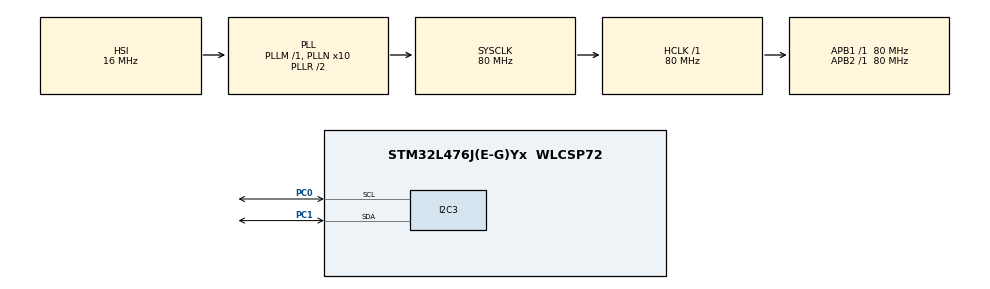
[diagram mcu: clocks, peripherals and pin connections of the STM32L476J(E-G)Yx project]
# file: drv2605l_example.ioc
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I2C3.Timing=0x10909CEC
Mcu.Family=STM32L4
Mcu.Name=STM32L476J(E-G)Yx
Mcu.Package=WLCSP72
NVIC.PriorityGroup=NVIC_PRIORITYGROUP_4
PC0.Mode=I2C
PC0.Signal=I2C3_SCL
PC1.Mode=I2C
PC1.Signal=I2C3_SDA
ProjectManager.HeapSize=0x200
ProjectManager.StackSize=0x400
ProjectManager.TargetToolchain=STM32CubeIDE
RCC.ADCFreq_Value=64000000
RCC.AHBFreq_Value=80000000
RCC.APB1Freq_Value=80000000
RCC.APB1TimFreq_Value=80000000
RCC.APB2Freq_Value=80000000
RCC.APB2TimFreq_Value=80000000
RCC.CortexFreq_Value=80000000
RCC.HCLKFreq_Value=80000000
RCC.HSE_VALUE=8000000
RCC.HSI_VALUE=16000000
RCC.LSE_VALUE=32768
RCC.MSI_VALUE=4000000
RCC.PLLN=10
RCC.PLLSourceVirtual=RCC_PLLSOURCE_HSI
RCC.SYSCLKFreq_VALUE=80000000
RCC.SYSCLKSource=RCC_SYSCLKSOURCE_PLLCLK
RCC.USBFreq_Value=64000000
RCC.VCOOutputFreq_Value=160000000
board=custom

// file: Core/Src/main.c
/* USER CODE BEGIN Header */
/**
  ******************************************************************************
  * @file           : main.c
  * @brief          : Main program body
  ******************************************************************************
  * @attention
  *
  * <h2><center>&copy; Copyright (c) 2021 STMicroelectronics.
  * All rights reserved.</center></h2>
  *
  * This software component is licensed by ST under BSD 3-Clause license,
  * the "License"; You may not use this file except in compliance with the
  * License. You may obtain a copy of the License at:
  *                        opensource.org/licenses/BSD-3-Clause
  *
  ******************************************************************************
  */
/* USER CODE END Header */
#include "main.h"

/* USER CODE BEGIN Includes */
#include "drv2605l.h"
/* USER CODE END Includes */

I2C_HandleTypeDef hi2c3;

void SystemClock_Config(void);
static void MX_GPIO_Init(void);
static void MX_I2C3_Init(void);

int main(void)
{

  /* MCU Configuration--------------------------------------------------------*/

  /* Reset of all peripherals, Initializes the Flash interface and the Systick. */
  HAL_Init();

  /* Configure the system clock */
  SystemClock_Config();

  /* Initialize all configured peripherals */
  MX_GPIO_Init();
  MX_I2C3_Init();
  HAL_I2C_Init(&hi2c3);
  /* USER CODE BEGIN 2 */

  drv2605l_init(&hi2c3); // Initialize the drv2605l with the correct I2C config

	drv2605l_set_mode(0x0); // Set mode to internal trigger input

	drv2605l_motor_select(0x36); // ERM Motor

	drv2605l_set_library(0x02); // Select ERM library. 1-5 & 7 for ERM motors, 6 for LRA motors

	int seq, wave;
  /* USER CODE END 2 */

  /* Infinite loop */
  while (1)
  {
  	seq = 0; // There are 8 sequence registers that can queue up to 8 waveforms
		for (wave = 1; wave <= 123; wave++) // There are 123 waveform effects
		{
			drv2605l_set_waveform(seq, wave);
			drv2605l_go();
			HAL_Delay(800); // Give it enough time to play waveform effect

			if (wave%8 == 0) // Each waveform register can queue 8 effects
			{
				seq++;
			}
			if (wave%64 == 0) // After the last register is used start over
			{
				seq = 0;
			}
		}
  }
}

void SystemClock_Config(void)
{
  RCC_OscInitTypeDef RCC_OscInitStruct = {0};
  RCC_ClkInitTypeDef RCC_ClkInitStruct = {0};

  /** Configure the main internal regulator output voltage
  */
  if (HAL_PWREx_ControlVoltageScaling(PWR_REGULATOR_VOLTAGE_SCALE1) != HAL_OK)
  {
    Error_Handler();
  }
  /** Initializes the RCC Oscillators according to the specified parameters
  * in the RCC_OscInitTypeDef structure.
  */
  RCC_OscInitStruct.OscillatorType = RCC_OSCILLATORTYPE_HSI;
  RCC_OscInitStruct.HSIState = RCC_HSI_ON;
  RCC_OscInitStruct.HSICalibrationValue = RCC_HSICALIBRATION_DEFAULT;
  RCC_OscInitStruct.PLL.PLLState = RCC_PLL_ON;
  RCC_OscInitStruct.PLL.PLLSource = RCC_PLLSOURCE_HSI;
  RCC_OscInitStruct.PLL.PLLM = 1;
  RCC_OscInitStruct.PLL.PLLN = 10;
  RCC_OscInitStruct.PLL.PLLP = RCC_PLLP_DIV7;
  RCC_OscInitStruct.PLL.PLLQ = RCC_PLLQ_DIV2;
  RCC_OscInitStruct.PLL.PLLR = RCC_PLLR_DIV2;
  if (HAL_RCC_OscConfig(&RCC_OscInitStruct) != HAL_OK)
  {
    Error_Handler();
  }
  /** Initializes the CPU, AHB and APB buses clocks
  */
  RCC_ClkInitStruct.ClockType = RCC_CLOCKTYPE_HCLK|RCC_CLOCKTYPE_SYSCLK
                              |RCC_CLOCKTYPE_PCLK1|RCC_CLOCKTYPE_PCLK2;
  RCC_ClkInitStruct.SYSCLKSource = RCC_SYSCLKSOURCE_PLLCLK;
  RCC_ClkInitStruct.AHBCLKDivider = RCC_SYSCLK_DIV1;
  RCC_ClkInitStruct.APB1CLKDivider = RCC_HCLK_DIV1;
  RCC_ClkInitStruct.APB2CLKDivider = RCC_HCLK_DIV1;

  if (HAL_RCC_ClockConfig(&RCC_ClkInitStruct, FLASH_LATENCY_4) != HAL_OK)
  {
    Error_Handler();
  }
}

static void MX_I2C3_Init(void)
{

  hi2c3.Instance = I2C3;
  hi2c3.Init.Timing = 0x10909CEC;
  hi2c3.Init.OwnAddress1 = 0;
  hi2c3.Init.AddressingMode = I2C_ADDRESSINGMODE_7BIT;
  hi2c3.Init.DualAddressMode = I2C_DUALADDRESS_DISABLE;
  hi2c3.Init.OwnAddress2 = 0;
  hi2c3.Init.OwnAddress2Masks = I2C_OA2_NOMASK;
  hi2c3.Init.GeneralCallMode = I2C_GENERALCALL_DISABLE;
  hi2c3.Init.NoStretchMode = I2C_NOSTRETCH_DISABLE;
  if (HAL_I2C_Init(&hi2c3) != HAL_OK)
  {
    Error_Handler();
  }
  /** Configure Analogue filter
  */
  if (HAL_I2CEx_ConfigAnalogFilter(&hi2c3, I2C_ANALOGFILTER_ENABLE) != HAL_OK)
  {
    Error_Handler();
  }
  /** Configure Digital filter
  */
  if (HAL_I2CEx_ConfigDigitalFilter(&hi2c3, 0) != HAL_OK)
  {
    Error_Handler();
  }

}

static void MX_GPIO_Init(void)
{

  /* GPIO Ports Clock Enable */
  __HAL_RCC_GPIOC_CLK_ENABLE();

}

void Error_Handler(void)
{
  __disable_irq();
  while (1)
  {
  }
}

/************************ (C) COPYRIGHT STMicroelectronics *****END OF FILE****/
